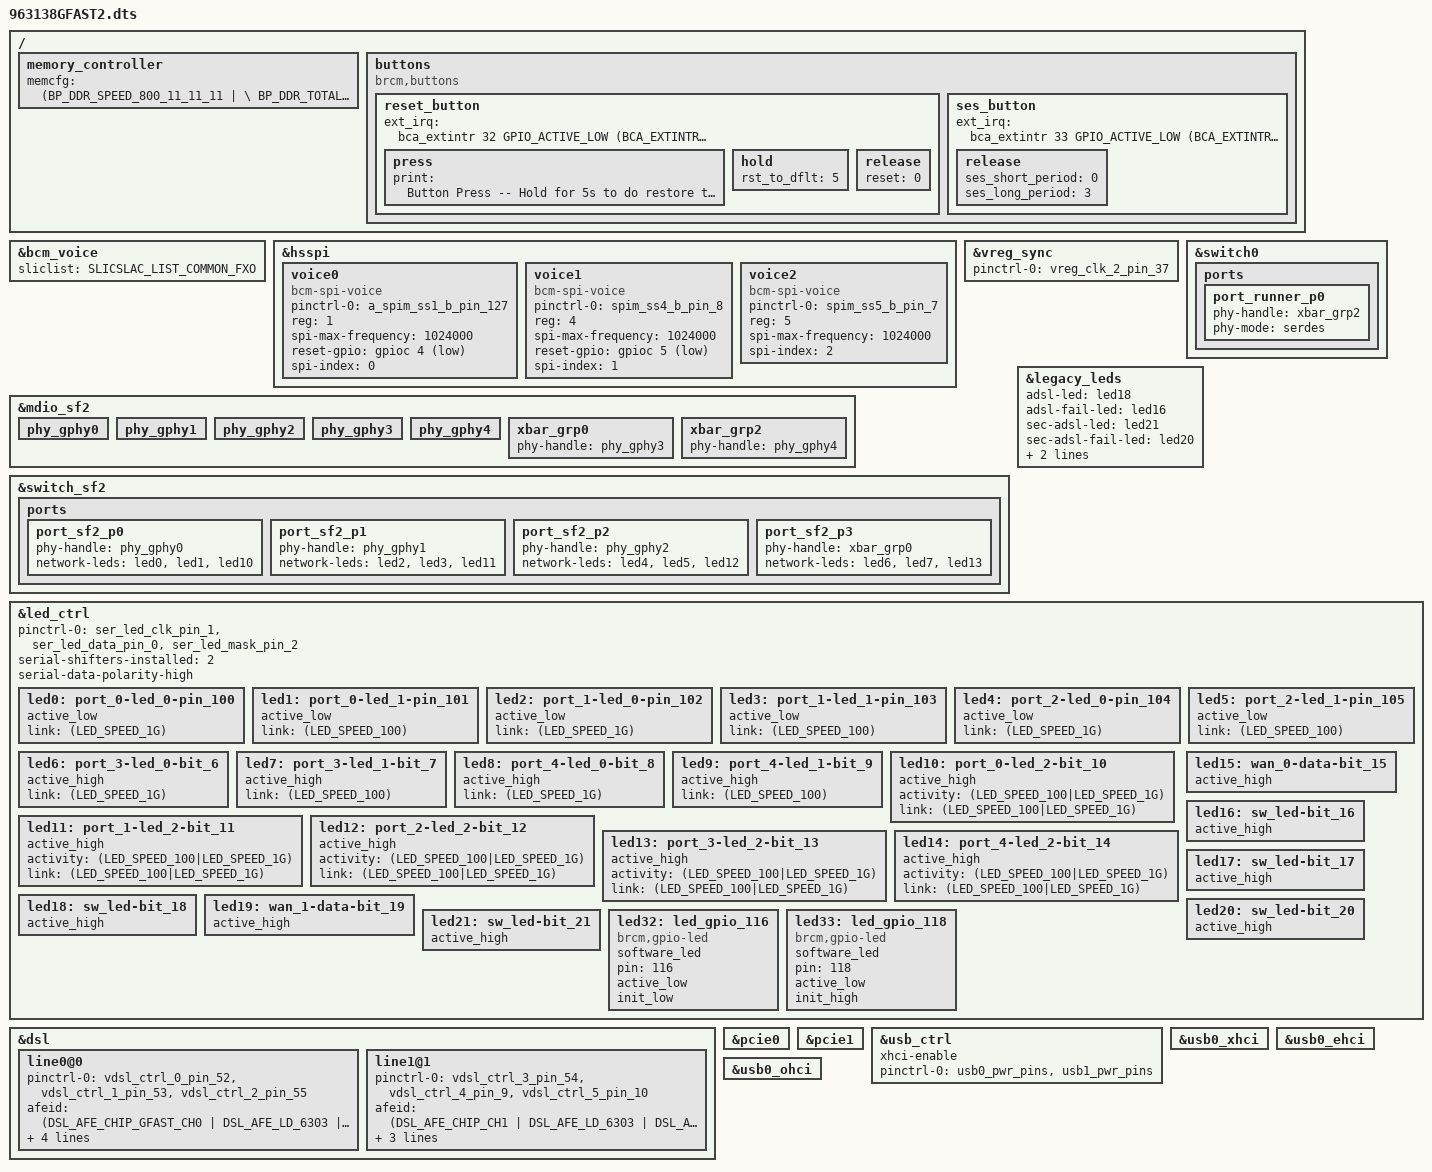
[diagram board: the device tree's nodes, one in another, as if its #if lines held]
#include "63138.dtsi"
#include "../bcm_voice.dtsi"

/ {
	memory_controller {
		memcfg = <(BP_DDR_SPEED_800_11_11_11   | \
			BP_DDR_TOTAL_SIZE_512MB  | \
			BP_DDR_DEVICE_WIDTH_16)>;
	};

	buttons {
		compatible = "brcm,buttons";
		reset_button {
			ext_irq = <&bca_extintr 32 GPIO_ACTIVE_LOW (BCA_EXTINTR_TYPE_LOW_LEVEL | BCA_EXTINTR_TYPE_SENSE_LEVEL)>;
			press {
				print = "Button Press -- Hold for 5s to do restore to default";
			};
			hold {
				rst_to_dflt = <5>;
			};
			release {
				reset = <0>;
			};	
		};
		ses_button {
			ext_irq = <&bca_extintr 33 GPIO_ACTIVE_LOW (BCA_EXTINTR_TYPE_LOW_LEVEL | BCA_EXTINTR_TYPE_SENSE_LEVEL)>;
			release {
				ses_short_period = <0>;
				ses_long_period = <3>;
			};
		};
	};
};

&bcm_voice{
	sliclist = SLICSLAC_LIST_COMMON_FXO;
 };

&hsspi {
	status = "okay";
	voice0 {
		pinctrl-0 = <&a_spim_ss1_b_pin_127>;
		pinctrl-names = "default";
		compatible = "bcm-spi-voice";
		reg = <1>; /* chip select 1 */
		spi-max-frequency = <1024000>;
		reset-gpio = <&gpioc 4 GPIO_ACTIVE_LOW>;
		spi-index = <0>;/* voice header index */
	};
	voice1 {
		pinctrl-0 = <&spim_ss4_b_pin_8>;
		pinctrl-names = "default";
		compatible = "bcm-spi-voice";
		reg = <4>; /* chip select 2 */
		spi-max-frequency = <1024000>;
		reset-gpio = <&gpioc 5 GPIO_ACTIVE_LOW>;
		spi-index = <1>;/* voice header index */
	};
	voice2 {
		pinctrl-0 = <&spim_ss5_b_pin_7>;
		pinctrl-names = "default";
		compatible = "bcm-spi-voice";
		reg = <5>; /* chip select 3 */
		spi-max-frequency = <1024000>;
		/*reset-gpio = NA;*/
		spi-index = <2>;/* voice header index */
	};
};

&vreg_sync {
		pinctrl-0 = <&vreg_clk_2_pin_37>;
		pinctrl-names = "default";
};

&mdio_sf2 {
        /* Port PHY mapping:
            port_runner_p1  <-->  port_sf2_p8 -###- port_sf2_p0 <------------------> phy_gphy0
                                               # #- port_sf2_p1 <------------------> phy_gphy1
                                               # #- port_sf2_p2 <------------------> phy_gphy2
                                               ###- port_sf2_p3 <--> xbar_grp0 -+-+- phy_gphy3
                                                 port_runner_p0 <--> xbar_grp2 -+-+- phy_gphy4
         */
	/* PHYs directly connected to SF2 */
	phy_gphy0 {
		status = "okay";
	};
	phy_gphy1 {
		status = "okay";
	};
	phy_gphy2 {
		status = "okay";
	};

	/* PHYs connected to crossbar */
	phy_gphy3 {
		status = "okay";
	};
	phy_gphy4 {
		status = "okay";
	};

	/* Crossbar groups */
	xbar_grp0 {
		phy-handle = <&phy_gphy3>;
		status = "okay";
	};
	xbar_grp2 {
		phy-handle = <&phy_gphy4>;
		status = "okay";
	};
};

&switch_sf2 {
	ports {
		/* ports connect directly */
		port_sf2_p0 {
			phy-handle = <&phy_gphy0>;
			network-leds = <&led0 &led1 &led10>;
			status = "okay";
		};

		port_sf2_p1 {
			phy-handle = <&phy_gphy1>;
			network-leds = <&led2 &led3 &led11>;
			status = "okay";
		};

		port_sf2_p2 {
			phy-handle = <&phy_gphy2>;
			network-leds = <&led4 &led5 &led12>;
			status = "okay";
		};

		/* ports connected to crossbar */
		port_sf2_p3 {
			phy-handle = <&xbar_grp0>;
			network-leds = <&led6 &led7 &led13>;
			status = "okay";
		};
	};
};

&switch0 {
	ports {
		
		port_runner_p0 {
			phy-handle = <&xbar_grp2>;
			phy-mode = "serdes";
			status = "okay";
		};
	};
};

&legacy_leds {
	adsl-led = <&led18>;
	adsl-fail-led = <&led16>;
	sec-adsl-led = <&led21>;
	sec-adsl-fail-led = <&led20>;
	wan-data-led = <&led15>;
	wl-sess-led = <&led17>;
};

&led_ctrl {
    pinctrl-names = "default";
    pinctrl-0 = <&ser_led_clk_pin_1 &ser_led_data_pin_0 &ser_led_mask_pin_2>;
    serial-shifters-installed = <2>;
    serial-data-polarity-high;

    led0: port_0-led_0-pin_100 {
        active_low;
        link = <(LED_SPEED_1G)>;
        status = "okay";
    };
    led1: port_0-led_1-pin_101 {
        active_low;
        link = <(LED_SPEED_100)>;
        status = "okay";
    };
    led2: port_1-led_0-pin_102 {
        active_low;
        link = <(LED_SPEED_1G)>;
        status = "okay";
    };
    led3: port_1-led_1-pin_103 {
        active_low;
        link = <(LED_SPEED_100)>;
        status = "okay";
    };
    led4: port_2-led_0-pin_104 {
        active_low;
        link = <(LED_SPEED_1G)>;
        status = "okay";
    };
    led5: port_2-led_1-pin_105 {
        active_low;
        link = <(LED_SPEED_100)>;
        status = "okay";
    };
    led6: port_3-led_0-bit_6 {
        active_high;
        link = <(LED_SPEED_1G)>;
        status = "okay";
    };
    led7: port_3-led_1-bit_7 {
        active_high;
        link = <(LED_SPEED_100)>;
        status = "okay";
    };
    led8: port_4-led_0-bit_8 {
        active_high;
        link = <(LED_SPEED_1G)>;
        status = "okay";
    };
    led9: port_4-led_1-bit_9 {
        active_high;
        link = <(LED_SPEED_100)>;
        status = "okay";
    };
    led10: port_0-led_2-bit_10 {
        active_high;
        activity = <(LED_SPEED_100|LED_SPEED_1G)>;
        link = <(LED_SPEED_100|LED_SPEED_1G)>;
        status = "okay";
    };
    led11: port_1-led_2-bit_11 {
        active_high;
        activity = <(LED_SPEED_100|LED_SPEED_1G)>;
        link = <(LED_SPEED_100|LED_SPEED_1G)>;
        status = "okay";
    };
    led12: port_2-led_2-bit_12 {
        active_high;
        activity = <(LED_SPEED_100|LED_SPEED_1G)>;
        link = <(LED_SPEED_100|LED_SPEED_1G)>;
        status = "okay";
    };
    led13: port_3-led_2-bit_13 {
        active_high;
        activity = <(LED_SPEED_100|LED_SPEED_1G)>;
        link = <(LED_SPEED_100|LED_SPEED_1G)>;
        status = "okay";
    };    
    led14: port_4-led_2-bit_14 {
        active_high;
        activity = <(LED_SPEED_100|LED_SPEED_1G)>;
        link = <(LED_SPEED_100|LED_SPEED_1G)>;
        status = "okay";
    };
    led15: wan_0-data-bit_15 {
        active_high;
        status = "okay";
    };
    led16: sw_led-bit_16 {
        active_high;
        status = "okay";
    };
    led17: sw_led-bit_17 {
        active_high;
        status = "okay";
    };
    led18: sw_led-bit_18 {
        active_high;
        status = "okay";
    };
    led19: wan_1-data-bit_19 {
        active_high;
        status = "okay";
    };
	led20: sw_led-bit_20 {
        active_high;
        status = "okay";
    };
	led21: sw_led-bit_21 {
        active_high;
        status = "okay";
    };
	/* power led */
	led32:led_gpio_116 {
		compatible = "brcm,gpio-led";
		software_led;
		pin = <116>;
		active_low;
        init_low;
	};
	/* power fail led */
	led33:led_gpio_118 {
		compatible = "brcm,gpio-led";
		software_led;
		pin = <118>;
		active_low;
        init_high;
	};

};

&dsl {
	line0@0 {
		pinctrl-0 = <&vdsl_ctrl_0_pin_52 &vdsl_ctrl_1_pin_53 &vdsl_ctrl_2_pin_55>;
		pinctrl-names = "default";

		afeid = <(DSL_AFE_CHIP_GFAST_CH0 | DSL_AFE_LD_6303 | DSL_AFE_FE_REV_6303_REV_12_3_40)>;
		afe-pwr-ctl = <DSL_AFE_VDSLCTL_0>;
		afe-data-ctl = <DSL_AFE_VDSLCTL_1>;
		afe-clk-ctl = <DSL_AFE_VDSLCTL_2>;

		relay-gpio = <&gpioc 3 GPIO_ACTIVE_HIGH>;
		
		status = "okay";
	};

	line1@1 {
		pinctrl-0 = <&vdsl_ctrl_3_pin_54 &vdsl_ctrl_4_pin_9 &vdsl_ctrl_5_pin_10>;
		pinctrl-names = "default";

		afeid = <(DSL_AFE_CHIP_CH1 | DSL_AFE_LD_6303 | DSL_AFE_FE_ANNEXA | DSL_AFE_FE_REV_6303_REV_12_3_40)>;
		afe-pwr-ctl = <DSL_AFE_VDSLCTL_3>;
		afe-data-ctl = <DSL_AFE_VDSLCTL_4>;
		afe-clk-ctl = <DSL_AFE_VDSLCTL_5>;
		status = "okay";
	};
};

#if defined(CONFIG_BCM_PCIE_HCD) || defined(CONFIG_BCM_PCIE_HCD_MODULE)
&pcie0 {
	status = "okay";
};
&pcie1 {
	status = "okay";
};
#endif //#if defined(CONFIG_BCM_PCIE_HCD) || defined(CONFIG_BCM_PCIE_HCD_MODULE)

&usb_ctrl {
	status = "okay";
	xhci-enable;
	pinctrl-names = "default";
	pinctrl-0 = <&usb0_pwr_pins &usb1_pwr_pins>;
};

&usb0_xhci {
	status = "okay";
};

&usb0_ehci {
	status = "okay";
};

&usb0_ohci {
	status = "okay";
};

